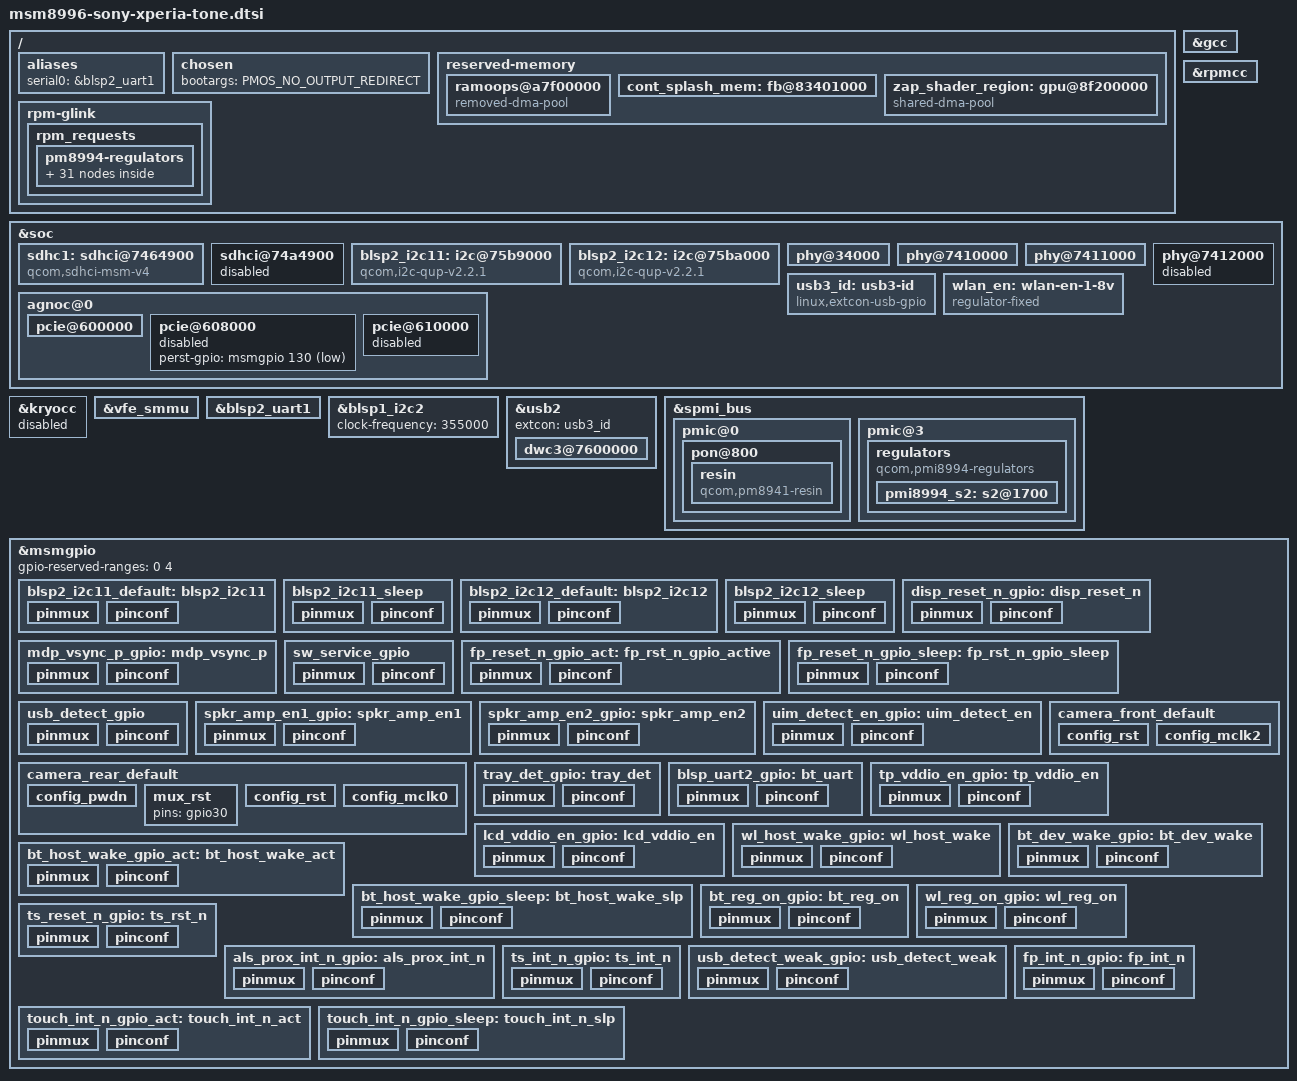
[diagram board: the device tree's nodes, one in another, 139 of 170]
// SPDX-License-Identifier: GPL-2.0
/* Copyright (C) 2016 Sony Mobile Communications Inc.
 * Copyright (c) 2019 AngeloGioacchino Del Regno <kholk11@gmail.com>
 */

#include "msm8996.dtsi"
#include "pm8994.dtsi"
#include "pmi8994.dtsi"
#include <dt-bindings/input/input.h>
#include <dt-bindings/input/gpio-keys.h>
#include <dt-bindings/gpio/gpio.h>
#include <dt-bindings/pinctrl/qcom,pmic-gpio.h>
#include <dt-bindings/pinctrl/qcom,pmic-mpp.h>

/ {
	aliases {
		serial0 = &blsp2_uart1;
	};

	chosen {
		bootargs = "PMOS_NO_OUTPUT_REDIRECT";
		#address-cells = <2>;
		#size-cells = <2>;
		ranges;
	};

	reserved-memory {
		ramoops@a7f00000 {
			compatible = "removed-dma-pool", "ramoops";
			no-map;
			reg = <0 0xa7f00000 0 0x100000>;
			record-size = <0x20000>;
			console-size = <0x40000>;
			ftrace-size = <0x20000>;
			pmsg-size = <0x20000>;
			ecc-size = <16>;
			status = "ok";
		};

		cont_splash_mem: fb@83401000 {
			no-map;
			reg = <0 0x83401000 0 0x23ff000>;
		};

		zap_shader_region: gpu@8f200000 {
			compatible = "shared-dma-pool";
			reg = <0x0 0x91700000 0x0 0xa00000>;
			no-map;
			status = "ok";
		};
	};

	rpm-glink {
		rpm_requests {
			pm8994-regulators {
				vdd_l1-supply = <&pm8994_s3>;
				vdd_l2_l26_l28-supply = <&pm8994_s3>;
				vdd_l3_l11-supply = <&pm8994_s3>;
				vdd_l4_l27_l31-supply = <&pm8994_s3>;
				vdd_l5_l7-supply = <&pm8994_s5>;
				vdd_l14_l15-supply = <&pm8994_s5>;
				vdd_l20_l21-supply = <&pm8994_s5>;
				vdd_l25-supply = <&pm8994_s3>;

				pm8994_s3: s3 {
					regulator-min-microvolt = <1300000>;
					regulator-max-microvolt = <1300000>;
				};

				pm8994_s4: s4 {
					regulator-min-microvolt = <1800000>;
					regulator-max-microvolt = <1800000>;
					regulator-always-on;
				};

				pm8994_s5: s5 {
					regulator-min-microvolt = <2150000>;
					regulator-max-microvolt = <2150000>;
				};

				pm8994_s7: s7 {
					regulator-min-microvolt = <800000>;
					regulator-max-microvolt = <800000>;
				};

				pm8994_l1: l1 {
					regulator-min-microvolt = <1000000>;
					regulator-max-microvolt = <1000000>;
				};

				pm8994_l2: l2 {
					regulator-min-microvolt = <1250000>;
					regulator-max-microvolt = <1250000>;
				};

				pm8994_l3: l3 {
					regulator-min-microvolt = <1100000>;
					regulator-max-microvolt = <1100000>;
				};

				pm8994_l4: l4 {
					regulator-min-microvolt = <1225000>;
					regulator-max-microvolt = <1225000>;
				};

				l6 {};

				l7 {};

				pm8994_l8: l8 {
					regulator-min-microvolt = <1800000>;
					regulator-max-microvolt = <1800000>;
				};

				pm8994_l9: l9 {
					regulator-min-microvolt = <1800000>;
					regulator-max-microvolt = <1800000>;
				};

				pm8994_l10: l10 {
					regulator-min-microvolt = <1800000>;
					regulator-max-microvolt = <1800000>;
				};

				l11 {};

				pm8994_l12: l12 {
					regulator-min-microvolt = <1800000>;
					regulator-max-microvolt = <1800000>;
				};

				pm8994_l13: l13 {
					regulator-min-microvolt = <1800000>;
					regulator-max-microvolt = <2950000>;
				};

				l14 {};

				pm8994_l15: l15 {
					regulator-min-microvolt = <1800000>;
					regulator-max-microvolt = <1800000>;
				};

				pm8994_l16: l16 {
					regulator-min-microvolt = <2700000>;
					regulator-max-microvolt = <2700000>;
				};

				pm8994_l17: l17 {
					regulator-min-microvolt = <2200000>;
					regulator-max-microvolt = <2500000>;
				};

				pm8994_l18: l18 {
					regulator-min-microvolt = <1800000>;
					regulator-max-microvolt = <1800000>;
				};

				pm8994_l20: l20 {
					regulator-min-microvolt = <2950000>;
					regulator-max-microvolt = <2950000>;
					regulator-allow-set-load;
				};

				pm8994_l21: l21 {
					regulator-min-microvolt = <2950000>;
					regulator-max-microvolt = <2950000>;
				};

				pm8994_l22: l22 {
					regulator-min-microvolt = <3000000>;
					regulator-max-microvolt = <3000000>;
				};

				pm8994_l23: l23 {
					regulator-min-microvolt = <2700000>;
					regulator-max-microvolt = <2700000>;
				};

				pm8994_l24: l24 {
					regulator-min-microvolt = <3075000>;
					regulator-max-microvolt = <3075000>;
					regulator-allow-set-load;
				};

				pm8994_l25: l25 {
					regulator-min-microvolt = <1200000>;
					regulator-max-microvolt = <1200000>;
					regulator-allow-set-load;
				};

				pm8994_l27: l27 {
					regulator-min-microvolt = <1000000>;
					regulator-max-microvolt = <1200000>;
				};

				pm8994_l28: l28 { /* This should be 1.0V for USB, 0.925 for DSI :\ */
					regulator-min-microvolt = <925000>;
					regulator-max-microvolt = <925000>;
					regulator-allow-set-load;
				};

				pm8994_l29: l29 {
					regulator-min-microvolt = <2700000>;
					regulator-max-microvolt = <2700000>;
				};

				pm8994_l32: l32 {
					regulator-min-microvolt = <1800000>;
					regulator-max-microvolt = <1800000>;
				};
			};
		};
	};
};

&gcc {
	status = "ok";
};

&rpmcc {
	status = "ok";
};

&soc {
	sdhc1: sdhci@7464900 {
		compatible = "qcom,sdhci-msm-v4";
		reg = <0x7464900 0x500>, <0x7464000 0x800>;
		reg-names = "hc_mem", "core_mem";

		interrupts = <0 141 IRQ_TYPE_LEVEL_HIGH>,
			     <0 134 IRQ_TYPE_LEVEL_HIGH>;
		interrupt-names = "hc_irq", "pwr_irq";

		clock-names = "iface", "core", "xo";
		clocks = <&gcc GCC_SDCC1_AHB_CLK>,
			 <&gcc GCC_SDCC1_APPS_CLK>,
			 <&xo_board>;

		pinctrl-names = "default";
		pinctrl-0 = <&sdc1_clk_on &sdc1_cmd_on &sdc1_data_on
				&sdc1_rclk_on>;

		mmc-hs400-1_8v;
		bus-width = <8>;
		non-removable;
		status = "ok";
	};

	sdhci@74a4900 {
		pinctrl-names = "default", "sleep";
		pinctrl-0 = <&sdc2_clk_on &sdc2_cmd_on &sdc2_data_on
				&tray_det_gpio>;
		pinctrl-1 = <&sdc2_clk_off &sdc2_cmd_off &sdc2_data_off
				&tray_det_gpio>;
		cd-gpios = <&msmgpio 40 GPIO_ACTIVE_LOW>;
		vmmc-supply = <&pm8994_l21>;
		vqmmc-supply = <&pm8994_l13>;
		status = "disabled";
	};

	blsp2_i2c11: i2c@75b9000 {
		compatible = "qcom,i2c-qup-v2.2.1";
		reg = <0x75b9000 0x1000>;
		interrupts = <GIC_SPI 102 IRQ_TYPE_LEVEL_HIGH>;
		clocks = <&gcc GCC_BLSP2_AHB_CLK>,
			<&gcc GCC_BLSP2_QUP5_I2C_APPS_CLK>;
		clock-names = "iface", "core";
		pinctrl-names = "default", "sleep";
		pinctrl-0 = <&blsp2_i2c11_default>;
		pinctrl-1 = <&blsp2_i2c11_sleep>;
		#address-cells = <1>;
		#size-cells = <0>;

		clock-frequency = <355000>;
		status = "ok";
	};

	blsp2_i2c12: i2c@75ba000 {
		compatible = "qcom,i2c-qup-v2.2.1";
		reg = <0x75ba000 0x1000>;
		interrupts = <GIC_SPI 102 IRQ_TYPE_LEVEL_HIGH>;
		clocks = <&gcc GCC_BLSP2_AHB_CLK>,
			<&gcc GCC_BLSP2_QUP6_I2C_APPS_CLK>;
		clock-names = "iface", "core";
		pinctrl-names = "default", "sleep";
		pinctrl-0 = <&blsp2_i2c12_default>;
		pinctrl-1 = <&blsp2_i2c12_sleep>;
		#address-cells = <1>;
		#size-cells = <0>;

		clock-frequency = <355000>;
		status = "ok";
	};

	// gpio_keys {
	// 	compatible = "gpio-keys";
	// 	input-name = "gpio-keys";
	// 	#address-cells = <1>;
	// 	#size-cells = <0>;
	// 	autorepeat;

	// 	button@0 {
	// 		label = "Volume Down";
	// 		gpios = <&pm8994_gpios 2 GPIO_ACTIVE_LOW>;
	// 		linux,input-type = <1>;
	// 		linux,code = <KEY_VOLUMEDOWN>;
	// 		wakeup-source;
	// 		debounce-interval = <15>;
	// 	};

	// 	button@1 {
	// 		label = "Volume Up";
	// 		gpios = <&pm8994_gpios 3 GPIO_ACTIVE_LOW>;
	// 		linux,input-type = <1>;
	// 		linux,code = <KEY_VOLUMEUP>;
	// 		wakeup-source;
	// 		debounce-interval = <15>;
	// 	};

	// 	button@2 {
	// 		label = "Camera Snapshot";
	// 		gpios = <&pm8994_gpios 4 GPIO_ACTIVE_LOW>;
	// 		linux,input-type = <1>;
	// 		linux,code = <KEY_CAMERA>;
	// 		wakeup-source;
	// 		wakeup-event-action = <EV_ACT_ASSERTED>;
	// 		debounce-interval = <15>;
	// 	};

	// 	button@3 {
	// 		label = "Camera Focus";
	// 		gpios = <&pm8994_gpios 5 GPIO_ACTIVE_LOW>;
	// 		linux,input-type = <1>;
	// 		linux,code = <KEY_CAMERA_FOCUS>;
	// 		wakeup-source;
	// 		debounce-interval = <15>;
	// 	};
	// };

	phy@34000 {
		status = "okay";
	};

	phy@7410000 {
		status = "okay";
	};

	phy@7411000 {
		status = "okay";
	};

	phy@7412000 {
		status = "disabled";
	};

	usb3_id: usb3-id {
		compatible = "linux,extcon-usb-gpio";
		id-gpio = <&msmgpio 24 GPIO_ACTIVE_LOW>;
		pinctrl-names = "default";
		pinctrl-0 = <&usb_detect_gpio>;
	};

	wlan_en: wlan-en-1-8v {
		pinctrl-names = "default";
		pinctrl-0 = <&wl_reg_on_gpio>;
		compatible = "regulator-fixed";
		regulator-name = "wlan-en-regulator";
		regulator-min-microvolt = <1800000>;
		regulator-max-microvolt = <1800000>;

		gpio = <&msmgpio 84 GPIO_ACTIVE_HIGH>;

		/* WLAN card specific delay */
		startup-delay-us = <70000>;
		enable-active-high;
	};

	agnoc@0 {
		pcie@600000 {
			status = "okay";
			perst-gpio = <&msmgpio 35 GPIO_ACTIVE_LOW>;
			wake-gpio = <&msmgpio 37 GPIO_ACTIVE_LOW>;
			vddpe-3v3-supply = <&wlan_en>;
		};

		pcie@608000 {
			status = "disabled";
			perst-gpio = <&msmgpio 130 GPIO_ACTIVE_LOW>;
		};

		pcie@610000 {
			status = "disabled";
			perst-gpio = <&msmgpio 114 GPIO_ACTIVE_LOW>;
			wake-gpio = <&msmgpio 116 GPIO_ACTIVE_LOW>;
		};
	};
};

&kryocc {
	status = "disabled";
};

&vfe_smmu {
	status = "ok";
};

&blsp2_uart1 {
	status = "ok";
	pinctrl-names = "default", "sleep";
	pinctrl-0 = <&blsp2_uart1_2pins_default>;
	pinctrl-1 = <&blsp2_uart1_2pins_sleep>;
};

&blsp1_i2c2 {
	clock-frequency = <355000>;
	status = "ok";
};

&usb2 {
	status = "okay";
	extcon = <&usb3_id>;

	dwc3@7600000 {
		extcon = <&usb3_id>;
		dr_mode = "peripheral";
		maximum-speed = "high-speed";
	};
};


&spmi_bus {
	pmic@0 {
		pon@800 {
			resin {
				compatible = "qcom,pm8941-resin";
				interrupts = <0x0 0x8 1 IRQ_TYPE_EDGE_BOTH>;
				debounce = <15625>;
				bias-pull-up;
				linux,code = <KEY_VOLUMEUP>;
			};
		};
	};

	// pmic@2 {
	// 	pmi8994_mpps: pmi-mpps {
	// 		compatible = "qcom,pmi8994-mpp"; /* TODO: Not supported! */
	// 		reg = <0xa000 0x400>;

	// 		interrupts = <0x2 0xa0 0 IRQ_TYPE_NONE>,
	// 			<0x2 0xa1 0 IRQ_TYPE_NONE>,
	// 			<0x2 0xa2 0 IRQ_TYPE_NONE>,
	// 			<0x2 0xa3 0 IRQ_TYPE_NONE>;
	// 		interrupt-names = "pmi8994_mpp1", "pmi8994_mpp2",
	// 				  "pmi8994_mpp3", "pmi8994_mpp4";

	// 		gpio-controller;
	// 		#gpio-cells = <2>;
	// 	};
	// };

	pmic@3 {
		regulators {
			compatible = "qcom,pmi8994-regulators";
			#address-cells = <1>;
			#size-cells = <1>;

			/* GPU GX GDSC Supply */
			pmi8994_s2: s2@1700 {
				reg = <0x1700 0x100>;
				status = "ok";
				regulator-min-microvolt = <400000>;
				regulator-max-microvolt = <1015000>;
				regulator-always-on;
			};
		};
	};
};

/* Pins */
&msmgpio {
	gpio-reserved-ranges = <0 4>;

	blsp2_i2c11_default: blsp2_i2c11 {
		pinmux {
			function = "blsp_i2c11";
			pins = "gpio60", "gpio61";
		};
		pinconf {
			pins = "gpio60", "gpio61";
			drive-strength = <16>;
			bias-disable;
		};
	};

	blsp2_i2c11_sleep: blsp2_i2c11_sleep {
		pinmux {
			function = "gpio";
			pins = "gpio60", "gpio61";
		};
		pinconf {
			pins = "gpio60", "gpio61";
			drive-strength = <2>;
			bias-disable;
		};
	};

	blsp2_i2c12_default: blsp2_i2c12 {
		pinmux {
			function = "blsp_i2c12";
			pins = "gpio87", "gpio88";
		};
		pinconf {
			pins = "gpio87", "gpio88";
			drive-strength = <16>;
			bias-disable;
		};
	};

	blsp2_i2c12_sleep: blsp2_i2c12_sleep {
		pinmux {
			function = "gpio";
			pins = "gpio87", "gpio88";
		};
		pinconf {
			pins = "gpio87", "gpio88";
			drive-strength = <2>;
			bias-disable;
		};
	};

	disp_reset_n_gpio: disp_reset_n {
		pinmux {
			pins = "gpio8";
			function = "gpio";
		};

		pinconf {
			pins = "gpio8";
			drive-strength = <2>;
			bias-disable;
		};
	};

	mdp_vsync_p_gpio: mdp_vsync_p {
		pinmux {
			pins = "gpio10";
			function = "mdp_vsync";
		};

		pinconf {
			pins = "gpio10";
			drive-strength = <2>;
			bias-disable;
		};
	};

	sw_service_gpio: sw_service_gpio {
		pinmux {
			pins = "gpio16";
			function = "gpio";
		};

		pinconf {
			pins = "gpio16";
			drive-strength = <2>;
			bias-pull-up;
		};
	};

	fp_reset_n_gpio_act: fp_rst_n_gpio_active {
		pinmux {
			pins = "gpio21";
			function = "gpio";
		};

		pinconf {
			pins = "gpio21";
			drive-strength = <2>;
			bias-disable;
			output-high;
		};
	};

	fp_reset_n_gpio_sleep: fp_rst_n_gpio_sleep {
		pinmux {
			pins = "gpio21";
			function = "gpio";
		};

		pinconf {
			pins = "gpio21";
			drive-strength = <2>;
			bias-disable;
			output-low;
		};
	};

	usb_detect_gpio: usb_detect_gpio {
		pinmux {
			pins = "gpio24";
			function = "gpio";
		};

		pinconf {
			pins = "gpio24";
			drive-strength = <2>;
			bias-disable;
			output-low;
		};
	};

	spkr_amp_en1_gpio: spkr_amp_en1 {
		pinmux {
			pins = "gpio27";
			function = "gpio";
		};

		pinconf {
			pins = "gpio27";
			drive-strength = <2>;
			bias-disable;
			output-low;
		};
	};

	spkr_amp_en2_gpio: spkr_amp_en2 {
		pinmux {
			pins = "gpio28";
			function = "gpio";
		};

		pinconf {
			pins = "gpio28";
			drive-strength = <2>;
			bias-disable;
			output-low;
		};
	};

	uim_detect_en_gpio: uim_detect_en {
		pinmux {
			pins = "gpio29";
			function = "gpio";
		};

		pinconf {
			pins = "gpio29";
			drive-strength = <2>;
			bias-disable;
			output-low;
		};
	};


	camera_rear_default {
		config_pwdn {
			drive-strength = <2>;
			output-low;
		};

		mux_rst {
			pins = "gpio30";
		};

		config_rst {
			pins = "gpio30";
			drive-strength = <2>;
			output-low;
		};

		config_mclk0 {
			drive-strength = <2>;
			output-low;
		};
	};

	camera_front_default {
		config_rst {
			drive-strength = <2>;
			output-low;
		};

		config_mclk2 {
			drive-strength = <2>;
			output-low;
		};
	};

	tray_det_gpio: tray_det {
		pinmux {
			pins = "gpio40";
			function = "gpio";
		};

		pinconf {
			pins = "gpio40";
			drive-strength = <2>;
			bias-disable;
		};
	};

	blsp_uart2_gpio: bt_uart {
		pinmux {
			function = "blsp_uart2";
			pins = "gpio41", "gpio42", "gpio43", "gpio44";
		};
		pinconf {
			pins = "gpio41", "gpio42", "gpio43", "gpio44";
			drive-strength = <2>;
			bias-disable;
		};
	};

	tp_vddio_en_gpio: tp_vddio_en {
		pinmux {
			pins = "gpio50";
			function = "gpio";
		};

		pinconf {
			pins = "gpio50";
			drive-strength = <2>;
			bias-disable;
			output-low;
		};
	};

	lcd_vddio_en_gpio: lcd_vddio_en {
		pinmux {
			pins = "gpio51";
			function = "gpio";
		};

		pinconf {
			pins = "gpio51";
			drive-strength = <2>;
			bias-disable;
			output-low;
		};
	};

	wl_host_wake_gpio: wl_host_wake {
		pinmux {
			pins = "gpio79";
			function = "gpio";
		};

		pinconf {
			pins = "gpio79";
			drive-strength = <2>;
			bias-pull-down;
		};
	};

	bt_dev_wake_gpio: bt_dev_wake {
		pinmux {
			pins = "gpio81";
			function = "gpio";
		};

		pinconf {
			pins = "gpio81";
			drive-strength = <2>;
			bias-disable;
			output-low;
		};
	};

	bt_host_wake_gpio_act: bt_host_wake_act {
		pinmux {
			pins = "gpio82";
			function = "gpio";
		};

		pinconf {
			pins = "gpio82";
			drive-strength = <2>;
			bias-disable;
		};
	};

	bt_host_wake_gpio_sleep: bt_host_wake_slp {
		pinmux {
			pins = "gpio82";
			function = "gpio";
		};

		pinconf {
			pins = "gpio82";
			drive-strength = <2>;
			bias-pull-down;
		};
	};

	bt_reg_on_gpio: bt_reg_on {
		pinmux {
			pins = "gpio83";
			function = "gpio";
		};

		pinconf {
			pins = "gpio83";
			drive-strength = <2>;
			bias-disable;
			output-low;
		};
	};

	wl_reg_on_gpio: wl_reg_on {
		pinmux {
			pins = "gpio84";
			function = "gpio";
		};

		pinconf {
			pins = "gpio84";
			drive-strength = <2>;
			bias-disable;
			output-low;
		};
	};

	ts_reset_n_gpio: ts_rst_n {
		pinmux {
			pins = "gpio89";
			function = "gpio";
		};

		pinconf {
			pins = "gpio89";
			drive-strength = <2>;
		};
	};

	als_prox_int_n_gpio: als_prox_int_n {
		pinmux {
			pins = "gpio120";
			function = "gpio";
		};

		pinconf {
			pins = "gpio120";
			drive-strength = <2>;
			bias-disable;
		};
	};

	ts_int_n_gpio: ts_int_n {
		pinmux {
			pins = "gpio125";
			function = "gpio";
		};

		pinconf {
			pins = "gpio125";
			drive-strength = <2>;
		};
	};

	usb_detect_weak_gpio: usb_detect_weak {
		pinmux {
			pins = "gpio130";
			function = "gpio";
		};

		pinconf {
			pins = "gpio130";
			drive-strength = <2>;
			bias-disable;
			output-low;
		};
	};

	fp_int_n_gpio: fp_int_n {
		pinmux {
			pins = "gpio132";
			function = "gpio";
		};

		pinconf {
			pins = "gpio132";
			drive-strength = <2>;
			bias-pull-down;
		};
	};

	touch_int_n_gpio_act: touch_int_n_act {
		pinmux {
			pins = "gpio125";
			function = "touch_int_n";
		};
		pinconf {
			pins = "gpio125";
			drive-strength = <2>;
			bias-pull-up;
		};
	};

	touch_int_n_gpio_sleep: touch_int_n_slp {
		pinmux {
			pins = "gpio125";
			function = "touch_int_n";
		};
		pinconf {
			pins = "gpio125";
			drive-strength = <2>;
			bias-pull-down;
		};
	};
};

// /* PMIC Pins */
// &pm8994_gpios {
// 	pinctrl-names = "default";
// 	pinctrl-0 = <&pm8994_gpio_1 &pm8994_vol_down_n &pm8994_vol_up_n
// 		     &pm8994_cam_snap_n &pm8994_cam_focus_n &pm8994_gpio_6
// 		     &pm8994_nfc_dload &pm8994_gpio_8 &pm8994_gpio_9
// 		     &pm8994_gpio_nfc_clk &pm8994_gpio_11 &pm8994_gpio_12
// 		     &pm8994_ear_en &pm8994_gpio_14 &pm8994_pm_divclk1
// 		     &pm8994_pmi_clk &pm8994_gpio_17 &pm8994_rome_sleep
// 		     &pm8994_gpio_19 &pm8994_gpio_22>;

// 	gpio-line-names =
// 		"NC",
// 		"VOL_DOWN_N",
// 		"VOL_UP_N",
// 		"SNAPSHOT_N",
// 		"FOCUS_N",
// 		"NC",
// 		"NFC_VEN",
// 		"NC",
// 		"NC",
// 		"NC",
// 		"NC",
// 		"NC",
// 		"EAR_EN",
// 		"NC",
// 		"PM_DIVCLK1",
// 		"PMI_CLK",
// 		"NC",
// 		"WL_SLEEP_CLK",
// 		"NC",
// 		"PMIC_SPON",
// 		"UIM_BATT_ALARM",
// 		"PMK_SLEEP_CLK";

// 	pm8994_gpio_1: pm_gpio1_nc {
// 		pins = "gpio1";
// 		function = PMIC_GPIO_FUNC_NORMAL;
// 		drive-push-pull;
// 		bias-high-impedance;
// 	};

// 	pm8994_vol_down_n: vol_down_n {
// 		pins = "gpio2";
// 		function = PMIC_GPIO_FUNC_NORMAL;
// 		drive-push-pull;
// 		input-enable;
// 		bias-pull-up;
// 		qcom,drive-strength = <PMIC_GPIO_STRENGTH_NO>;
// 		power-source = <PM8994_GPIO_S4>;
// 	};

// 	pm8994_vol_up_n: vol_up_n {
// 		pins = "gpio3";
// 		function = PMIC_GPIO_FUNC_NORMAL;
// 		drive-push-pull;
// 		input-enable;
// 		bias-pull-up;
// 		power-source = <PM8994_GPIO_S4>;
// 	};

// 	pm8994_cam_snap_n: camera_snapshot_n {
// 		pins = "gpio4";
// 		function = PMIC_GPIO_FUNC_NORMAL;
// 		drive-push-pull;
// 		input-enable;
// 		bias-pull-up;
// 		qcom,drive-strength = <PMIC_GPIO_STRENGTH_NO>;
// 		power-source = <PM8994_GPIO_S4>;
// 	};

// 	pm8994_cam_focus_n: camera_focus_n {
// 		pins = "gpio5";
// 		function = PMIC_GPIO_FUNC_NORMAL;
// 		drive-push-pull;
// 		input-enable;
// 		bias-pull-up;
// 		qcom,drive-strength = <PMIC_GPIO_STRENGTH_NO>;
// 		power-source = <PM8994_GPIO_S4>;
// 	};

// 	pm8994_gpio_6: pm_gpio6_nc {
// 		pins = "gpio6";
// 		function = PMIC_GPIO_FUNC_NORMAL;
// 		drive-push-pull;
// 		bias-high-impedance;
// 		power-source = <PM8994_GPIO_VPH>;
// 	};

// 	pm8994_nfc_dload: nfc_download {
// 		pins = "gpio7";
// 		function = PMIC_GPIO_FUNC_NORMAL;
// 		output-low;
// 		drive-push-pull;
// 		bias-disable;
// 		qcom,drive-strength = <PMIC_GPIO_STRENGTH_LOW>;
// 		power-source = <PM8994_GPIO_S4>;
// 	};

// 	pm8994_gpio_8: pm_gpio8_nc {
// 		pins = "gpio8";
// 		function = PMIC_GPIO_FUNC_NORMAL;
// 		output-low;
// 		drive-push-pull;
// 		bias-high-impedance;
// 		qcom,drive-strength = <PMIC_GPIO_STRENGTH_NO>;
// 		power-source = <PM8994_GPIO_VPH>;
// 	};

// 	pm8994_gpio_9: pm_gpio9_nc {
// 		pins = "gpio9";
// 		function = PMIC_GPIO_FUNC_NORMAL;
// 		output-high;
// 		drive-push-pull;
// 		bias-high-impedance;
// 		qcom,drive-strength = <PMIC_GPIO_STRENGTH_LOW>;
// 		power-source = <PM8994_GPIO_VPH>;
// 	};

// 	pm8994_gpio_nfc_clk: nfc_clock {
// 		pins = "gpio10";
// 		function = PMIC_GPIO_FUNC_NORMAL;
// 		input-enable;
// 		drive-push-pull;
// 		bias-pull-down;
// 		qcom,drive-strength = <PMIC_GPIO_STRENGTH_NO>;
// 		power-source = <PM8994_GPIO_S4>;
// 	};

// 	pm8994_gpio_11: pm_gpio11_nc {
// 		pins = "gpio11";
// 		function = PMIC_GPIO_FUNC_NORMAL;
// 		drive-push-pull;
// 		bias-high-impedance;
// 		power-source = <PM8994_GPIO_VPH>;
// 	};

// 	pm8994_gpio_12: pm_gpio12_nc {
// 		pins = "gpio12";
// 		function = PMIC_GPIO_FUNC_NORMAL;
// 		drive-push-pull;
// 		bias-high-impedance;
// 		power-source = <PM8994_GPIO_VPH>;
// 	};

// 	pm8994_ear_en: ear_enable {
// 		pins = "gpio13";
// 		function = PMIC_GPIO_FUNC_NORMAL;
// 		output-high;
// 		drive-push-pull;
// 		bias-disable;
// 		qcom,drive-strength = <PMIC_GPIO_STRENGTH_LOW>;
// 		power-source = <PM8994_GPIO_S4>;
// 	};

// 	pm8994_gpio_14: pm_gpio14_nc {
// 		pins = "gpio14";
// 		function = PMIC_GPIO_FUNC_NORMAL;
// 		drive-push-pull;
// 		input-enable;
// 		bias-high-impedance;
// 		qcom,drive-strength = <PMIC_GPIO_STRENGTH_LOW>;
// 		power-source = <PM8994_GPIO_VPH>;
// 	};

// 	pm8994_pm_divclk1: pm_divclk1_gpio {
// 		pins = "gpio15";
// 		function = "func1";
// 		output-low;
// 		drive-push-pull;
// 		bias-high-impedance;
// 		qcom,drive-strength = <PMIC_GPIO_STRENGTH_LOW>;
// 		power-source = <PM8994_GPIO_VPH>;
// 	};

// 	pm8994_pmi_clk: pmi_clk_gpio {
// 		pins = "gpio16";
// 		function = PMIC_GPIO_FUNC_NORMAL;
// 		drive-push-pull;
// 	};

// 	pm8994_gpio_17: pm_gpio17_nc {
// 		pins = "gpio17";
// 		function = PMIC_GPIO_FUNC_NORMAL;
// 		drive-push-pull;
// 		bias-high-impedance;
// 		power-source = <PM8994_GPIO_VPH>;
// 	};

// 	pm8994_rome_sleep: rome_sleep {
// 		pins = "gpio18";
// 		function = PMIC_GPIO_FUNC_FUNC2;
// 		output-low;
// 		drive-push-pull;
// 		bias-disable;
// 		qcom,drive-strength = <PMIC_GPIO_STRENGTH_MED>;
// 		power-source = <PM8994_GPIO_S4>;
// 	};

// 	pm8994_gpio_19: pm_gpio19_nc {
// 		pins = "gpio19";
// 		function = PMIC_GPIO_FUNC_NORMAL;
// 		output-low;
// 		drive-push-pull;
// 		bias-high-impedance;
// 		qcom,drive-strength = <PMIC_GPIO_STRENGTH_NO>;
// 		power-source = <PM8994_GPIO_VPH>;
// 	};

// 	pm8994_gpio_22: pm_gpio22_nc {
// 		pins = "gpio17";
// 		function = PMIC_GPIO_FUNC_NORMAL;
// 		drive-push-pull;
// 		bias-high-impedance;
// 		power-source = <PM8994_GPIO_VPH>;
// 	};
// };

// &pm8994_mpps {
// 	pinctrl-names = "default";
// 	pinctrl-0 = <&pm8994_mpp_lcd_id_adc &pm8994_mpp4
// 			&pm8994_mpp_flash_th &pm8994_mpp6_def
// 			&pm8994_mpp_rf_id>;

// 	gpio-line-names =
// 		"SDC_UIM_VBIAS",
// 		"LCD_ID_ADC",
// 		"VREF_DACX",
// 		"NC",
// 		"FLASH_THERM",
// 		"NC",
// 		"NC",
// 		"RF_ID";

// 	pm8994_mpp_lcd_id_adc: lcd_id_adc_mpp {
// 		pins = "mpp2";
// 		function = PMIC_MPP_FUNC_ANALOG;
// 		input-enable;
// 		qcom,amux-route = <PMIC_MPP_AMUX_ROUTE_CH6>;
// 	};

// 	pm8994_mpp4: pm_mpp4_nc {
// 		pins = "mpp4";
// 		function = PMIC_MPP_FUNC_DIGITAL;
// 		bias-high-impedance;
// 		power-source = <PM8994_GPIO_VPH>;
// 	};

// 	pm8994_mpp_flash_th: flash_therm_mpp {
// 		pins = "mpp5";
// 		function = PMIC_MPP_FUNC_ANALOG;
// 		input-enable;
// 		qcom,amux-route = <PMIC_MPP_AMUX_ROUTE_CH5>;
// 	};

// 	pm8994_mpp6_def: mpp6_nc {
// 		pins = "mpp6";
// 		function = PMIC_MPP_FUNC_DIGITAL;
// 		bias-high-impedance;
// 	};

// 	pm8994_mpp_rf_id: rf_id_mpp {
// 		pins = "mpp8";
// 		function = PMIC_MPP_FUNC_ANALOG;
// 		input-enable;
// 		qcom,amux-route = <PMIC_MPP_AMUX_ROUTE_CH8>;
// 	};
// };

// &pmi8994_gpios {
// 	pinctrl-names = "default";
// 	pinctrl-0 = <&pmi8994_vib_ldo_en &pmi8994_gpio_2 &pmi8994_gpio_3
// 		     &pmi8994_gpio_4 &pmi8994_gpio_5 &pmi8994_gpio_6
// 		     &pmi8994_gpio_7 &pmi8994_gpio_8 &pmi8994_usb_switch_sel
// 		     &pmi8994_gpio_10>;

// 	gpio-line-names =
// 		"VIB_LDO_EN",
// 		"NC",
// 		"NC",
// 		"NC",
// 		"NC",
// 		"NC",
// 		"NC",
// 		"NC",
// 		"USB_SWITCH_SEL",
// 		"NC";

// 	pmi8994_vib_ldo_en: vib_ldo_en_gpio {
// 		pins = "gpio1";
// 		function = PMIC_GPIO_FUNC_NORMAL;
// 		drive-push-pull;
// 		output-low;
// 		bias-disable;
// 		power-source = <PM8994_GPIO_S4>;
// 	};

// 	pmi8994_gpio_2: pmi_gpio2_nc {
// 		pins = "gpio2";
// 		function = PMIC_GPIO_FUNC_NORMAL;
// 		drive-push-pull;
// 		input-enable;
// 		bias-high-impedance;
// 		qcom,drive-strength = <PMIC_GPIO_STRENGTH_NO>;
// 		power-source = <PM8994_GPIO_VPH>;
// 	};

// 	pmi8994_gpio_3: pmi_gpio3_nc {
// 		pins = "gpio3";
// 		function = PMIC_GPIO_FUNC_NORMAL;
// 		drive-push-pull;
// 		input-enable;
// 		bias-high-impedance;
// 		qcom,drive-strength = <PMIC_GPIO_STRENGTH_NO>;
// 		power-source = <PM8994_GPIO_VPH>;
// 	};

// 	pmi8994_gpio_4: pmi_gpio4_nc {
// 		pins = "gpio4";
// 		function = PMIC_GPIO_FUNC_NORMAL;
// 		drive-push-pull;
// 		output-high;
// 		qcom,drive-strength = <PMIC_GPIO_STRENGTH_LOW>;
// 		power-source = <PM8994_GPIO_S4>;
// 	};

// 	pmi8994_gpio_5: pmi_gpio5_nc {
// 		pins = "gpio5";
// 		function = PMIC_GPIO_FUNC_NORMAL;
// 		drive-push-pull;
// 		output-high;
// 		qcom,drive-strength = <PMIC_GPIO_STRENGTH_NO>;
// 		power-source = <PM8994_GPIO_S4>;
// 	};

// 	pmi8994_gpio_6: pmi_gpio6_nc {
// 		pins = "gpio6";
// 		function = PMIC_GPIO_FUNC_NORMAL;
// 		drive-push-pull;
// 		output-high;
// 		qcom,drive-strength = <PMIC_GPIO_STRENGTH_LOW>;
// 		power-source = <PM8994_GPIO_S4>;
// 	};

// 	pmi8994_gpio_7: pmi_gpio7_nc {
// 		pins = "gpio7";
// 		function = PMIC_GPIO_FUNC_NORMAL;
// 		drive-push-pull;
// 		output-high;
// 		qcom,drive-strength = <PMIC_GPIO_STRENGTH_LOW>;
// 		power-source = <PM8994_GPIO_S4>;
// 	};

// 	pmi8994_gpio_8: pmi_gpio8_nc {
// 		pins = "gpio8";
// 		function = PMIC_GPIO_FUNC_NORMAL;
// 		drive-push-pull;
// 		output-high;
// 		qcom,drive-strength = <PMIC_GPIO_STRENGTH_LOW>;
// 		power-source = <PM8994_GPIO_S4>;
// 	};

// 	pmi8994_usb_switch_sel: usb_switch_sel {
// 		pins = "gpio9";
// 		function = PMIC_GPIO_FUNC_NORMAL;
// 		drive-push-pull;
// 	};

// 	pmi8994_gpio_10: pmi_gpio10_nc {
// 		pins = "gpio10";
// 		function = PMIC_GPIO_FUNC_NORMAL;
// 		output-low;
// 		drive-push-pull;
// 		bias-disable;
// 		qcom,drive-strength = <PMIC_GPIO_STRENGTH_NO>;
// 		power-source = <PM8994_GPIO_S4>;
// 	};
// };

// &pmi8994_mpps {
// 	pinctrl-names = "default";
// 	pinctrl-0 = <&pmi8994_mpp_usbid_dis &pmi8994_mpp_flash_led_now
// 			&pmi8994_mpp4_nc>;

// 	gpio-line-names =
// 		"USB_ID_DISCHG",
// 		"FLASH_LED_NOW",
// 		"PMI_SPON",
// 		"NC",
// 		"NC";

// 	pmi8994_mpp_usbid_dis: usb_id_dischg_mpp {
// 		pins = "mpp1";
// 		function = PMIC_MPP_FUNC_DIGITAL;
// 		input-enable;
// 		power-source = <PM8994_GPIO_S4>;
// 	};

// 	pmi8994_mpp_flash_led_now: flash_led_now_mpp {
// 		pins = "mpp2";
// 		function = PMIC_MPP_FUNC_DIGITAL;
// 		input-enable;
// 		power-source = <PM8994_GPIO_S4>;
// 	};

// 	pmi8994_mpp4_nc: pmi_mpp4_nc {
// 		pins = "mpp4";
// 		function = PMIC_MPP_FUNC_DIGITAL;
// 		bias-high-impedance;
// 		power-source = <PM8994_MPP_VPH>;
// 	};
// };

